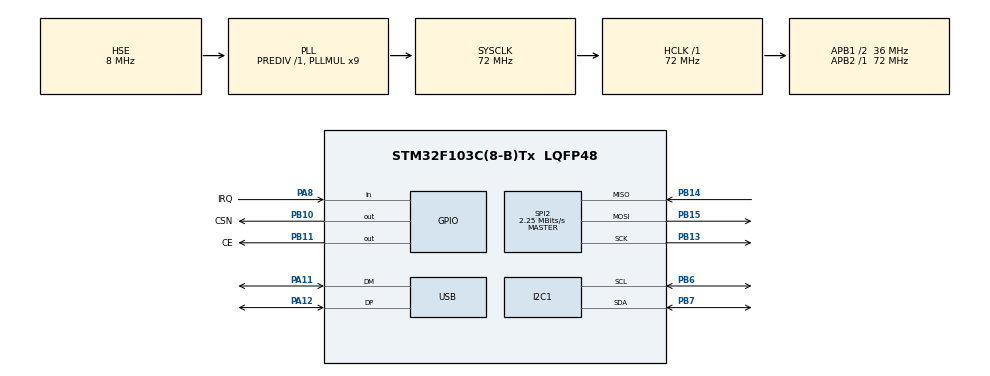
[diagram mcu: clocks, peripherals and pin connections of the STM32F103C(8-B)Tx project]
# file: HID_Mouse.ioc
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Mcu.Family=STM32F1
Mcu.Name=STM32F103C(8-B)Tx
Mcu.Package=LQFP48
NVIC.PriorityGroup=NVIC_PRIORITYGROUP_4
NVIC.USB_LP_CAN1_RX0_IRQn=true\:0\:0\:false\:false\:true\:false\:true\:true
PA11.Mode=Device
PA11.Signal=USB_DM
PA12.Mode=Device
PA12.Signal=USB_DP
PA13.Mode=Serial_Wire
PA13.Signal=SYS_JTMS-SWDIO
PA14.Mode=Serial_Wire
PA14.Signal=SYS_JTCK-SWCLK
PA8.GPIO_Label=IRQ
PA8.GPIO_PuPd=GPIO_PULLUP
PA8.Signal=GPIO_Input
PB10.GPIO_Label=CSN
PB10.GPIO_Speed=GPIO_SPEED_FREQ_MEDIUM
PB10.PinState=GPIO_PIN_SET
PB10.Signal=GPIO_Output
PB11.GPIO_Label=CE
PB11.GPIO_Speed=GPIO_SPEED_FREQ_MEDIUM
PB11.PinState=GPIO_PIN_SET
PB11.Signal=GPIO_Output
PB13.GPIO_Speed=GPIO_SPEED_FREQ_MEDIUM
PB13.Mode=Full_Duplex_Master
PB13.Signal=SPI2_SCK
PB14.GPIO_PuPd=GPIO_PULLUP
PB14.Mode=Full_Duplex_Master
PB14.Signal=SPI2_MISO
PB15.GPIO_Speed=GPIO_SPEED_FREQ_MEDIUM
PB15.Mode=Full_Duplex_Master
PB15.Signal=SPI2_MOSI
PB6.Mode=I2C
PB6.Signal=I2C1_SCL
PB7.Mode=I2C
PB7.Signal=I2C1_SDA
PD0-OSC_IN.Mode=HSE-External-Oscillator
PD0-OSC_IN.Signal=RCC_OSC_IN
PD1-OSC_OUT.Mode=HSE-External-Oscillator
PD1-OSC_OUT.Signal=RCC_OSC_OUT
ProjectManager.HeapSize=0x200
ProjectManager.StackSize=0x400
ProjectManager.TargetToolchain=MDK-ARM V5.32
RCC.ADCPresc=RCC_ADCPCLK2_DIV6
RCC.AHBFreq_Value=72000000
RCC.APB1CLKDivider=RCC_HCLK_DIV2
RCC.APB1Freq_Value=36000000
RCC.APB1TimFreq_Value=72000000
RCC.APB2Freq_Value=72000000
RCC.APB2TimFreq_Value=72000000
RCC.HCLKFreq_Value=72000000
RCC.PLLMUL=RCC_PLL_MUL9
RCC.SYSCLKFreq_VALUE=72000000
RCC.SYSCLKSource=RCC_SYSCLKSOURCE_PLLCLK
RCC.USBFreq_Value=48000000
RCC.USBPrescaler=RCC_USBCLKSOURCE_PLL_DIV1_5
SPI2.BaudRatePrescaler=SPI_BAUDRATEPRESCALER_16
SPI2.CalculateBaudRate=2.25 MBits/s
SPI2.Direction=SPI_DIRECTION_2LINES
SPI2.Mode=SPI_MODE_MASTER
SPI2.VirtualType=VM_MASTER
USB_DEVICE.CLASS_NAME_FS=HID
USB_DEVICE.VirtualMode=Hid
USB_DEVICE.VirtualModeFS=Hid_FS
VP_USB_DEVICE_VS_USB_DEVICE_HID_FS.Mode=HID_FS
board=custom

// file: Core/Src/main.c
/* USER CODE BEGIN Header */
/**
  ******************************************************************************
  * @file           : main.c
  * @brief          : Main program body
  ******************************************************************************
  * @attention
  *
  * Copyright (c) 2025 STMicroelectronics.
  * All rights reserved.
  *
  * This software is licensed under terms that can be found in the LICENSE file
  * in the root directory of this software component.
  * If no LICENSE file comes with this software, it is provided AS-IS.
  *
  ******************************************************************************
  */
/* USER CODE END Header */
#include "main.h"
#include "i2c.h"
#include "spi.h"
#include "usb_device.h"
#include "gpio.h"

/* USER CODE BEGIN Includes */
#include "NRF24L01.h"
#include "OLED.h"
#include "usbd_hid.h"

extern USBD_HandleTypeDef hUsbDeviceFS;
/* USER CODE END Includes */

void SystemClock_Config(void);

int main(void)
{

  /* MCU Configuration--------------------------------------------------------*/

  /* Reset of all peripherals, Initializes the Flash interface and the Systick. */
  HAL_Init();

  /* Configure the system clock */
  SystemClock_Config();

  /* Initialize all configured peripherals */
  MX_GPIO_Init();
  MX_USB_DEVICE_Init();
  MX_I2C1_Init();
  MX_SPI2_Init();
//  /* USER CODE BEGIN 2 */
	OLED_Init();
	OLED_Clear();
	NRF24L01_Init();
	uint8_t HID_Buffer[4] = {0};
	uint8_t Buf[32]={0};
//	uint8_t TimeOUT;
  /* USER CODE END 2 */

  /* Infinite loop */
  /* USER CODE BEGIN WHILE */
  while (1)
  {
		if(R_IRQ()==0)
		{
			Receive(Buf);
		}
		HID_Buffer[0] = Buf[0];
    HID_Buffer[1] = Buf[1];
    HID_Buffer[2] = Buf[2];
		HID_Buffer[3] = Buf[3];
    USBD_HID_SendReport(&hUsbDeviceFS,HID_Buffer,4);
    /* USER CODE END WHILE */

  }
}

void SystemClock_Config(void)
{
  RCC_OscInitTypeDef RCC_OscInitStruct = {0};
  RCC_ClkInitTypeDef RCC_ClkInitStruct = {0};
  RCC_PeriphCLKInitTypeDef PeriphClkInit = {0};

  /** Initializes the RCC Oscillators according to the specified parameters
  * in the RCC_OscInitTypeDef structure.
  */
  RCC_OscInitStruct.OscillatorType = RCC_OSCILLATORTYPE_HSE;
  RCC_OscInitStruct.HSEState = RCC_HSE_ON;
  RCC_OscInitStruct.HSEPredivValue = RCC_HSE_PREDIV_DIV1;
  RCC_OscInitStruct.HSIState = RCC_HSI_ON;
  RCC_OscInitStruct.PLL.PLLState = RCC_PLL_ON;
  RCC_OscInitStruct.PLL.PLLSource = RCC_PLLSOURCE_HSE;
  RCC_OscInitStruct.PLL.PLLMUL = RCC_PLL_MUL9;
  if (HAL_RCC_OscConfig(&RCC_OscInitStruct) != HAL_OK)
  {
    Error_Handler();
  }

  /** Initializes the CPU, AHB and APB buses clocks
  */
  RCC_ClkInitStruct.ClockType = RCC_CLOCKTYPE_HCLK|RCC_CLOCKTYPE_SYSCLK
                              |RCC_CLOCKTYPE_PCLK1|RCC_CLOCKTYPE_PCLK2;
  RCC_ClkInitStruct.SYSCLKSource = RCC_SYSCLKSOURCE_PLLCLK;
  RCC_ClkInitStruct.AHBCLKDivider = RCC_SYSCLK_DIV1;
  RCC_ClkInitStruct.APB1CLKDivider = RCC_HCLK_DIV2;
  RCC_ClkInitStruct.APB2CLKDivider = RCC_HCLK_DIV1;

  if (HAL_RCC_ClockConfig(&RCC_ClkInitStruct, FLASH_LATENCY_2) != HAL_OK)
  {
    Error_Handler();
  }
  PeriphClkInit.PeriphClockSelection = RCC_PERIPHCLK_USB;
  PeriphClkInit.UsbClockSelection = RCC_USBCLKSOURCE_PLL_DIV1_5;
  if (HAL_RCCEx_PeriphCLKConfig(&PeriphClkInit) != HAL_OK)
  {
    Error_Handler();
  }
}

void Error_Handler(void)
{
  __disable_irq();
  while (1)
  {
  }
}
